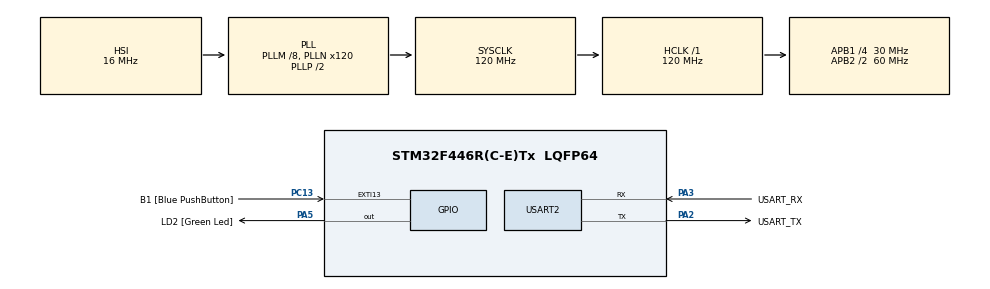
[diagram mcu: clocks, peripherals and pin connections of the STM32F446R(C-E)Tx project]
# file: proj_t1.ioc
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Mcu.Family=STM32F4
PC15-OSC32_OUT.Mode=LSE-External-Oscillator
PH0-OSC_IN.Signal=RCC_OSC_IN
RCC.CortexFreq_Value=120000000
PC13.Signal=GPXTI13
PA14.GPIO_Label=TCK
PC13.GPIO_Label=B1 [Blue PushButton]
RCC.APB1CLKDivider=RCC_HCLK_DIV4
PC14-OSC32_IN.Signal=RCC_OSC32_IN
RCC.SYSCLKSource=RCC_SYSCLKSOURCE_PLLCLK
ProjectManager.StackSize=0x1200
PA13.Signal=SYS_JTMS-SWDIO
PA3.Mode=Asynchronous
ProjectManager.TargetToolchain=STM32CubeIDE
RCC.HCLKFreq_Value=120000000
RCC.APB2TimFreq_Value=120000000
RCC.USBFreq_Value=120000000
PC15-OSC32_OUT.Signal=RCC_OSC32_OUT
RCC.AHBFreq_Value=120000000
PH0-OSC_IN.Mode=HSE-External-Oscillator
PA5.Signal=GPIO_Output
RCC.HSE_VALUE=8000000
board=NUCLEO-F446RE
RCC.VCOOutputFreq_Value=240000000
RCC.APB2Freq_Value=60000000
PC14-OSC32_IN.Mode=LSE-External-Oscillator
PA14.Mode=Serial_Wire
PH1-OSC_OUT.Signal=RCC_OSC_OUT
PA13.Mode=Serial_Wire
Mcu.Name=STM32F446R(C-E)Tx
PA2.Signal=USART2_TX
PA13.GPIO_Label=TMS
RCC.FLatency-AdvancedSettings=FLASH_LATENCY_3
PH1-OSC_OUT.Mode=HSE-External-Oscillator
RCC.48MHZClocksFreq_Value=84000000
PB3.Signal=SYS_JTDO-SWO
RCC.SYSCLKFreq_VALUE=120000000
Mcu.Package=LQFP64
PA5.GPIO_Label=LD2 [Green Led]
PC13.GPIO_ModeDefaultEXTI=GPIO_MODE_IT_FALLING
USART2.VirtualMode=VM_ASYNC
PA2.GPIO_Label=USART_TX
PA14.Signal=SYS_JTCK-SWCLK
ProjectManager.HeapSize=0x800
RCC.HSI_VALUE=16000000
NVIC.PriorityGroup=NVIC_PRIORITYGROUP_0
RCC.APB2CLKDivider=RCC_HCLK_DIV2
RCC.PLLM=8
RCC.PLLN=120
RCC.APB1TimFreq_Value=60000000
PA2.Mode=Asynchronous
RCC.APB1Freq_Value=30000000
PA3.GPIO_Label=USART_RX
PA3.Signal=USART2_RX
PB3.GPIO_Label=SWO

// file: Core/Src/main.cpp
/* USER CODE BEGIN Header */
/**
  ******************************************************************************
  * @file           : main.c
  * @brief          : Main program body
  ******************************************************************************
  * @attention
  *
  * <h2><center>&copy; Copyright (c) 2021 STMicroelectronics.
  * All rights reserved.</center></h2>
  *
  * This software component is licensed by ST under BSD 3-Clause license,
  * the "License"; You may not use this file except in compliance with the
  * License. You may obtain a copy of the License at:
  *                        opensource.org/licenses/BSD-3-Clause
  *
  ******************************************************************************
  */
/* USER CODE END Header */
#include <stdio.h>
extern "C" {
#include "main.h"
}
//#include "debug.h"
#include "string.h"
#include "sine_model.h"
#include "tensorflow/lite/micro/kernels/all_ops_resolver.h"
#include "tensorflow/lite/micro/micro_error_reporter.h"
#include "tensorflow/lite/micro/micro_interpreter.h"
#include "tensorflow/lite/schema/schema_generated.h"
#include "tensorflow/lite/version.h"

UART_HandleTypeDef huart2;

namespace
{
tflite::ErrorReporter* error_reporter = nullptr;
const tflite::Model* model = nullptr;
tflite::MicroInterpreter* interpreter = nullptr;
TfLiteTensor* input = nullptr;
TfLiteTensor* output = nullptr;

// Create an area of memory to use for input, output, and intermediate arrays.
// Finding the minimum value for your model may require some trial and error.
constexpr uint32_t kTensorArenaSize = 2 * 1024;
uint8_t tensor_arena[kTensorArenaSize];
}//namespace
// This constant determines the number of inferences to perform across the range
// of x values defined above. Since each inference takes time, the higher this
// number, the more time it will take to run through the entire range. The value
// of this constant can be tuned so that one full cycle takes a desired amount
// of time. Since different devices take different amounts of time to perform
// inference, this value should be defined per-device.
// A larger number than the default to make the animation smoother
const uint16_t INFERENCE_PER_CYCLE = 70;
const float INPUT_RANGE = 2.f * 3.14159265359f;
//UART_HandleTypeDef DebugUartHandler;

void SystemClock_Config(void);
static void error_handler(void);
static void MX_GPIO_Init(void);
static void MX_USART2_UART_Init(void);

/* USER CODE BEGIN 0 */
void handle_output(tflite::ErrorReporter* error_reporter, float x_value, float y_value)
{
	// Log the current X and Y values
	TF_LITE_REPORT_ERROR(error_reporter, "%f,%f\n", x_value, y_value);

	// A custom function can be implemented and used here to do something with the x and y values.
	// In my case I will be plotting sine wave on an LCD.
	//LCD_Output(x_value, y_value);
}
/* USER CODE END 0 */

int main(void)
{

  /* MCU Configuration--------------------------------------------------------*/

  /* Reset of all peripherals, Initializes the Flash interface and the Systick. */
  HAL_Init();

  /* Configure the system clock */
  SystemClock_Config();

  /* Initialize all configured peripherals */
  MX_GPIO_Init();
  MX_USART2_UART_Init();
  /* USER CODE BEGIN 2 */
  uint8_t *tbuf = (uint8_t*) "Hello\n";
  /* USER CODE END 2 */
  static tflite::MicroErrorReporter micro_error_reporter;
   error_reporter = &micro_error_reporter;

    	// Map the model into a usable data structure. This doesn't involve any
    	// copying or parsing, it's a very lightweight operation.
      model = tflite::GetModel(sine_model);

    	if(model->version() != TFLITE_SCHEMA_VERSION)
    	{
    		TF_LITE_REPORT_ERROR(error_reporter,
    	                         "Model provided is schema version %d not equal "
    	                         "to supported version %d.",
    	                         model->version(), TFLITE_SCHEMA_VERSION);
    	    return 0;
    	}

    	// This pulls in all the operation implementations we need.
    	static tflite::ops::micro::AllOpsResolver resolver;

    	// Build an interpreter to run the model with.
    	static tflite::MicroInterpreter static_interpreter(model, resolver, tensor_arena, kTensorArenaSize, error_reporter);
    	interpreter = &static_interpreter;

    	// Allocate memory from the tensor_arena for the model's tensors.
    	TfLiteStatus allocate_status = interpreter->AllocateTensors();
    	if (allocate_status != kTfLiteOk)
    	{
    	    TF_LITE_REPORT_ERROR(error_reporter, "AllocateTensors() failed");
    	    return 0;
    	}

    	// Obtain pointers to the model's input and output tensors.
    	input = interpreter->input(0);
    	output = interpreter->output(0);
  /* Infinite loop */
    	float unitValuePerDevision = INPUT_RANGE / static_cast<float>(INFERENCE_PER_CYCLE);

  while (1)
  {
	  /*HAL_UART_Transmit(&huart2, tbuf, strlen((char *)tbuf), HAL_MAX_DELAY);
	  HAL_Delay(1000);
	  HAL_GPIO_TogglePin(GPIOA, GPIO_PIN_5);*/
	  for(uint16_t inferenceCount = 0; inferenceCount <= INFERENCE_PER_CYCLE; inferenceCount++)
	          {
	  	        float x_val = static_cast<float>(inferenceCount) * unitValuePerDevision;

	  	        // Place our calculated x value in the model's input tensor
	  	        input->data.f[0] = x_val;

	  	        // Run inference, and report any error
	  	        TfLiteStatus invoke_status = interpreter->Invoke();
	  	        if (invoke_status != kTfLiteOk)
	  	        {
	  	            TF_LITE_REPORT_ERROR(error_reporter, "Invoke failed on x_val: %f\n", static_cast<float>(x_val));
	  	            return 0;
	  	        }

	  	        // Read the predicted y value from the model's output tensor
	  	        float y_val = output->data.f[0];
	  	        handle_output(error_reporter, x_val, y_val);
	          }
  }
}

void SystemClock_Config(void)
{
  RCC_OscInitTypeDef RCC_OscInitStruct = {0};
  RCC_ClkInitTypeDef RCC_ClkInitStruct = {0};

  /** Configure the main internal regulator output voltage
  */
  __HAL_RCC_PWR_CLK_ENABLE();
  __HAL_PWR_VOLTAGESCALING_CONFIG(PWR_REGULATOR_VOLTAGE_SCALE3);
  /** Initializes the RCC Oscillators according to the specified parameters
  * in the RCC_OscInitTypeDef structure.
  */
  RCC_OscInitStruct.OscillatorType = RCC_OSCILLATORTYPE_HSI;
  RCC_OscInitStruct.HSIState = RCC_HSI_ON;
  RCC_OscInitStruct.HSICalibrationValue = RCC_HSICALIBRATION_DEFAULT;
  RCC_OscInitStruct.PLL.PLLState = RCC_PLL_ON;
  RCC_OscInitStruct.PLL.PLLSource = RCC_PLLSOURCE_HSI;
  RCC_OscInitStruct.PLL.PLLM = 8;
  RCC_OscInitStruct.PLL.PLLN = 120;
  RCC_OscInitStruct.PLL.PLLP = RCC_PLLP_DIV2;
  RCC_OscInitStruct.PLL.PLLQ = 2;
  RCC_OscInitStruct.PLL.PLLR = 2;
  if (HAL_RCC_OscConfig(&RCC_OscInitStruct) != HAL_OK)
  {
    error_handler();
  }
  /** Initializes the CPU, AHB and APB buses clocks
  */
  RCC_ClkInitStruct.ClockType = RCC_CLOCKTYPE_HCLK|RCC_CLOCKTYPE_SYSCLK
                              |RCC_CLOCKTYPE_PCLK1|RCC_CLOCKTYPE_PCLK2;
  RCC_ClkInitStruct.SYSCLKSource = RCC_SYSCLKSOURCE_PLLCLK;
  RCC_ClkInitStruct.AHBCLKDivider = RCC_SYSCLK_DIV1;
  RCC_ClkInitStruct.APB1CLKDivider = RCC_HCLK_DIV4;
  RCC_ClkInitStruct.APB2CLKDivider = RCC_HCLK_DIV2;

  if (HAL_RCC_ClockConfig(&RCC_ClkInitStruct, FLASH_LATENCY_3) != HAL_OK)
  {
    error_handler();
  }
}

static void MX_USART2_UART_Init(void)
{

  huart2.Instance = USART2;
  huart2.Init.BaudRate = 115200;
  huart2.Init.WordLength = UART_WORDLENGTH_8B;
  huart2.Init.StopBits = UART_STOPBITS_1;
  huart2.Init.Parity = UART_PARITY_NONE;
  huart2.Init.Mode = UART_MODE_TX_RX;
  huart2.Init.HwFlowCtl = UART_HWCONTROL_NONE;
  huart2.Init.OverSampling = UART_OVERSAMPLING_16;
  if (HAL_UART_Init(&huart2) != HAL_OK)
  {
    error_handler();
  }

}

static void MX_GPIO_Init(void)
{
  GPIO_InitTypeDef GPIO_InitStruct = {0};

  /* GPIO Ports Clock Enable */
  __HAL_RCC_GPIOC_CLK_ENABLE();
  __HAL_RCC_GPIOH_CLK_ENABLE();
  __HAL_RCC_GPIOA_CLK_ENABLE();
  __HAL_RCC_GPIOB_CLK_ENABLE();

  /*Configure GPIO pin Output Level */
  HAL_GPIO_WritePin(LD2_GPIO_Port, LD2_Pin, GPIO_PIN_RESET);

  /*Configure GPIO pin : B1_Pin */
  GPIO_InitStruct.Pin = B1_Pin;
  GPIO_InitStruct.Mode = GPIO_MODE_IT_FALLING;
  GPIO_InitStruct.Pull = GPIO_NOPULL;
  HAL_GPIO_Init(B1_GPIO_Port, &GPIO_InitStruct);

  /*Configure GPIO pin : LD2_Pin */
  GPIO_InitStruct.Pin = LD2_Pin;
  GPIO_InitStruct.Mode = GPIO_MODE_OUTPUT_PP;
  GPIO_InitStruct.Pull = GPIO_NOPULL;
  GPIO_InitStruct.Speed = GPIO_SPEED_FREQ_LOW;
  HAL_GPIO_Init(LD2_GPIO_Port, &GPIO_InitStruct);

}

void error_handler(void)
{
  /* USER CODE BEGIN Error_Handler_Debug */
  /* User can add his own implementation to report the HAL error return state */
  __disable_irq();
  while (1)
  {
	  HAL_GPIO_TogglePin(GPIOA, GPIO_PIN_5);
	  HAL_Delay(1000);
  }
  /* USER CODE END Error_Handler_Debug */
}

/************************ (C) COPYRIGHT STMicroelectronics *****END OF FILE****/
